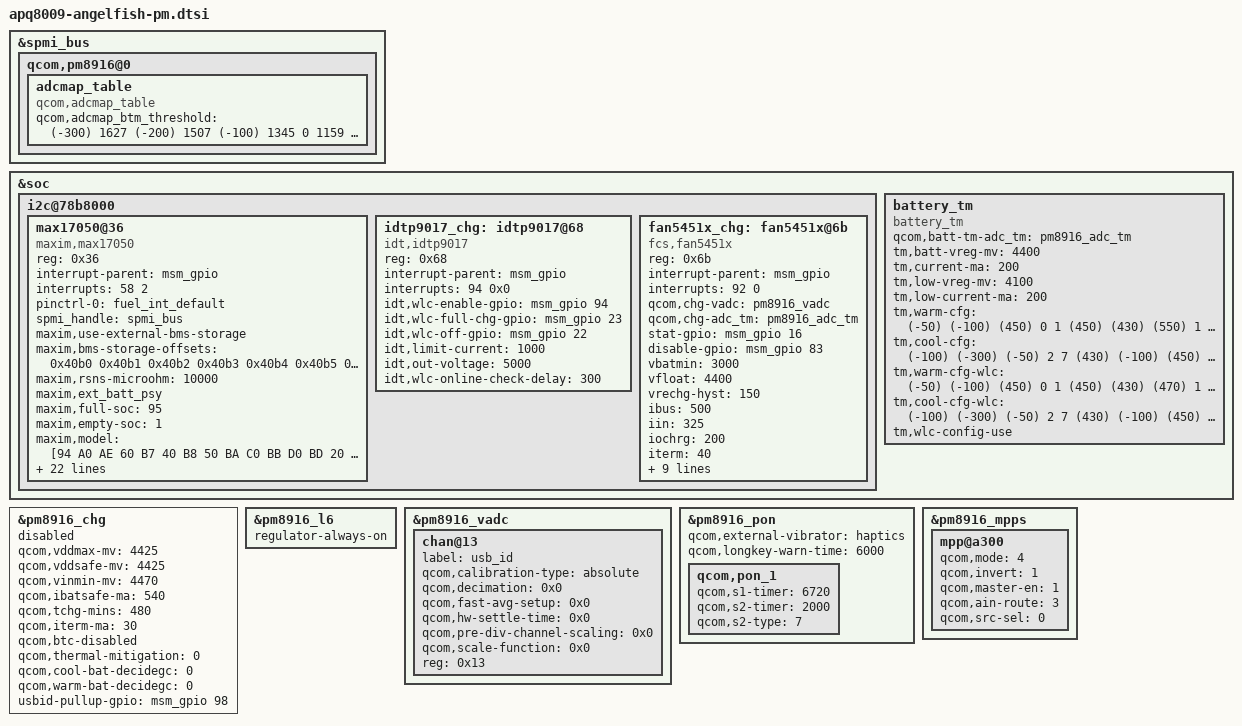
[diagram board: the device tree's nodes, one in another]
/* Copyright (c) 2016, LGE Inc. All rights reserved.
 *
 * This program is free software; you can redistribute it and/or modify
 * it under the terms of the GNU General Public License version 2 and
 * only version 2 as published by the Free Software Foundation.
 *
 * This program is distributed in the hope that it will be useful,
 * but WITHOUT ANY WARRANTY; without even the implied warranty of
 * MERCHANTABILITY or FITNESS FOR A PARTICULAR PURPOSE.  See the
 * GNU General Public License for more details.
 */

&spmi_bus {
	qcom,pm8916@0 {
		/*
		 * Since negative numbers are not allowed in device trees,
		 * the first two digits here specify if the last two are
		 * negative: 0 == positive, 1 == negative.
		 */
		adcmap_table {
			compatible = "qcom,adcmap_table";
			status = "okay";
			qcom,adcmap_btm_threshold = <
				(-300) 1627
				(-200) 1507
				(-100) 1345
				0 1159
				10 1139
				20 1120
				30 1101
				40 1082
				50 1064
				60 1045
				70 1026
				80 1008
				90 989
				100 972
				110 954
				120 936
				130 919
				140 902
				150 885
				160 869
				170 853
				180 837
				190 822
				200 807
				210 792
				220 777
				230 763
				240 750
				250 737
				260 724
				270 711
				280 699
				290 687
				300 675
				310 664
				320 653
				330 643
				340 633
				350 623
				360 613
				370 604
				380 595
				390 586
				400 578
				410 570
				420 562
				430 555
				440 547
				450 540
				460 533
				470 527
				480 521
				490 515
				500 509
				510 503
				520 498
				530 492
				540 487
				550 482
				560 478
				570 473
				580 469
				590 465
				600 461
				610 457
				620 453
				630 449
				640 446
				650 442
				660 439
				670 436
				680 433
				690 430
				700 427
				710 425
				720 422
				730 420
				740 417
				750 415
				760 413
				770 411
				780 409
				790 407>;
		};
	};
};

&soc {
	i2c@78b8000 {
		max17050@36 {
			status = "ok";
			compatible = "maxim,max17050";
			reg = <0x36>;
			interrupt-parent = <&msm_gpio>;
			interrupts = <58 2>;
			pinctrl-names = "default";
			pinctrl-0 = <&fuel_int_default>;
			spmi_handle = <&spmi_bus>;

			maxim,use-external-bms-storage;
			maxim,bms-storage-offsets = /bits/ 16 <
				0x40b0 0x40b1 0x40b2 0x40b3
				0x40b4 0x40b5 0x40b6>;

			maxim,rsns-microohm = <10000>;
			maxim,ext_batt_psy;
			maxim,full-soc = <95>;
			maxim,empty-soc = <1>;

			maxim,model = [94 A0 AE 60 B7 40 B8 50
					BA C0 BB D0 BD 20 BE 00
					C0 10 C1 50 C4 50 C7 E0
					CB 00 CE 40 D3 30 D9 70
					00 50 02 20 17 80 0E 40
					11 30 0D 00 26 60 0F 10
					13 40 0A F0 07 70 08 30
					06 F0 07 E0 06 C0 06 C0
					01 00 01 00 01 00 01 00
					01 00 01 00 01 00 01 00
					01 00 01 00 01 00 01 00
					01 00 01 00 01 00 01 00];

			maxim,config = <0x2104>;
			maxim,filtercfg = <0x87A4>;
			maxim,relaxcfg = <0x506B>;
			maxim,learncfg = <0x2603>;
			maxim,fullsocthr = <0x5F00>;
			maxim,iavg_empty = <0x0175>;
			maxim,rcomp0 = <0x0037>;
			maxim,tempco = <0x2D3A>;
			maxim,ichgterm = <0x00A0>;
			maxim,tgain = <0xE932>;
			maxim,toff = <0x2381>;
			maxim,vempty = <0xA05F>;
			maxim,qrtable00 = <0x2A00>;
			maxim,qrtable10 = <0x1483>;
			maxim,qrtable20 = <0x0A00>;
			maxim,qrtable30 = <0x0780>;
			maxim,capacity = <0x01D3>;
			maxim,vf_fullcap = <0x01D3>;
			maxim,cycles = <0x0060>;
			maxim,dpacc = <0x0C80>;
			maxim,param-version = <0x4>;
			maxim,dynamic_soc;
		};

		idtp9017_chg: idtp9017@68 {
			compatible = "idt,idtp9017";
			status = "ok";
			reg = <0x68>;
			interrupt-parent = <&msm_gpio>;
			interrupts = <94 0x0>;
			idt,wlc-enable-gpio = <&msm_gpio 94 0>;
			idt,wlc-full-chg-gpio = <&msm_gpio 23 0>;
			idt,wlc-off-gpio = <&msm_gpio 22 0>;
			idt,limit-current = <1000>; /* To check charging current */
			idt,out-voltage = <5000>;
			idt,wlc-online-check-delay = <300>; /* 5*60secs */
		};

		fan5451x_chg: fan5451x@6b {
			status = "ok";
			compatible = "fcs,fan5451x";
			reg = <0x6b>;
			interrupt-parent = <&msm_gpio>;
			interrupts = <92 0>;

			qcom,chg-vadc = <&pm8916_vadc>;
			qcom,chg-adc_tm = <&pm8916_adc_tm>;
			stat-gpio = <&msm_gpio 16 0x00>;
			disable-gpio = <&msm_gpio 83 0x00>;

			vbatmin = <3000>;    //CC start voltage 3.0V
			vfloat = <4400>;     //vbatmax
			vrechg-hyst = <150>; //rechg = vfloat - (vrechg-hyst)
			ibus = <500>;        //iusb for vbus
			iin = <325>;         //iusb for wlc
			iochrg = <200>;      //CC current
			iterm = <40>;        //term current
			prechg = <200>;      //pre charge current
			topoff-enable = <0>; //post charging flag
			vbusovp = <10500>;   //ovd for usb
			vbuslim = <4560>;    //uvd for usb
			vinovp = <10500>;    //ovd for wireless
			vinlim = <4560>;     //uvd for wireless
			fctmr = <0>;         //fast charge timer off
			fcs,embedded-battery;
			support-sw-eoc;
		};
	};

	battery_tm: battery_tm {
		compatible = "battery_tm";
		status = "ok";
		qcom,batt-tm-adc_tm = <&pm8916_adc_tm>;
		tm,batt-vreg-mv = <4400>;
		tm,current-ma = <200>;
		tm,low-vreg-mv = <4100>;
		tm,low-current-ma = <200>;
		tm,warm-cfg = <
			 (-50) (-100) (450) 0 1
			 (450)  (430) (550) 1 2
			 (550)  (430) (600) 2 2
			 (600)  (430) (790) 3 2>;
		tm,cool-cfg = <
			(-100) (-300) (-50) 2 7
			 (430) (-100) (450) 0 1>;
		tm,warm-cfg-wlc = <
			 (-50) (-100) (450) 0 1
			 (450)  (430) (470) 1 2
			 (470)  (430) (600) 2 2
			 (600)  (430) (790) 3 2>;
		tm,cool-cfg-wlc = <
			(-100) (-300) (-50) 2 7
			 (430) (-100) (450) 0 1>;
		tm,wlc-config-use;
	};
};

&pm8916_chg {
	status = "disabled";
	qcom,vddmax-mv = <4425>;
	qcom,vddsafe-mv = <4425>;
	qcom,vinmin-mv = <4470>;
	qcom,ibatsafe-ma = <540>;
	qcom,tchg-mins = <480>;
	qcom,iterm-ma = <30>;
	qcom,btc-disabled;
	qcom,thermal-mitigation = <0>; /* disabled */
	qcom,cool-bat-decidegc = <0>;  /* disabled */
	qcom,warm-bat-decidegc = <0>;  /* disabled */
	usbid-pullup-gpio = <&msm_gpio 98 0x00>;
};

&pm8916_l6{
	regulator-always-on;
};

&pm8916_vadc {
	chan@13 {
		label = "usb_id";
		qcom,calibration-type = "absolute";
		qcom,decimation = <0x0>;
		qcom,fast-avg-setup = <0x0>;
		qcom,hw-settle-time = <0x0>;
		qcom,pre-div-channel-scaling = <0x0>;
		qcom,scale-function = <0x0>;
		reg = <0x13>;
	};
};

&pm8916_pon {
	qcom,external-vibrator = <&haptics>;
	qcom,longkey-warn-time = <6000>;
	qcom,pon_1 {
		qcom,s1-timer = <6720>;
		qcom,s2-timer = <2000>;
		qcom,s2-type = <7>;
	};
};

&pm8916_mpps {
	mpp@a300 { // MPP 4 For PM_USB_ID ADC
		qcom,mode = <4>;      // MODE_CTL: ANALOG_INPUT
		qcom,invert = <1>;    // MODE_CTL: ANALOG Enable
		qcom,master-en = <1>; // EN_CTL: MPP Enabled
		qcom,ain-route = <3>; // ANA_IN_CTL: HKADC8
		qcom,src-sel = <0>;   // MODE_CTL: Source 0
	};
};
